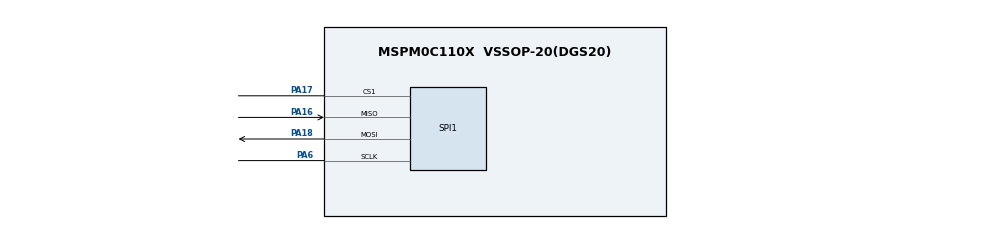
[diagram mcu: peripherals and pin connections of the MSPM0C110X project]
// @cliArgs --device "MSPM0C110X" --package "VSSOP-20(DGS20)" --part "Default"
// @cliArgs --board /ti/boards/LP_MSPM0C1104 --rtos nortos

/**
 * Import the modules used in this configuration.
 */
const SPI    = scripting.addModule("/ti/driverlib/SPI", {}, false);
const SPI1   = SPI.addInstance();
const SYSCTL = scripting.addModule("/ti/driverlib/SYSCTL");
const GPIO   = scripting.addModule("/ti/driverlib/GPIO", {}, false);
const GPIO1  = GPIO.addInstance();

/**
 * Write custom configuration values to the imported modules.
 */
SPI1.$name                              = "SPI_0";
SPI1.mode                               = "PERIPHERAL";
SPI1.enabledInterrupts                  = ["RX"];
SPI1.rxFifoThreshold                    = "DL_SPI_RX_FIFO_LEVEL_1_4_FULL";
SPI1.peripheralChipSelect               = "1";
SPI1.peripheral.$assign                 = "SPI0";
SPI1.peripheral.sclkPin.$assign         = "PA6";
SPI1.peripheral.mosiPin.$assign         = "PA18";
SPI1.peripheral.misoPin.$assign         = "PA16";
SPI1.peripheral.cs1Pin.$assign          = "PA17";

GPIO1.$name                          = "GPIO_LEDS";
GPIO1.associatedPins.create(2);
GPIO1.associatedPins[0].$name        = "USER_LED_1";
GPIO1.associatedPins[0].initialValue = "SET";
GPIO1.associatedPins[0].assignedPin  = "22";
GPIO1.associatedPins[1].$name        = "USER_TEST";
GPIO1.associatedPins[1].assignedPin  = "2";
GPIO1.associatedPins[1].initialValue = "SET";

const Board = scripting.addModule("/ti/driverlib/Board", {}, false);

SYSCTL.clockTreeEn = true;
